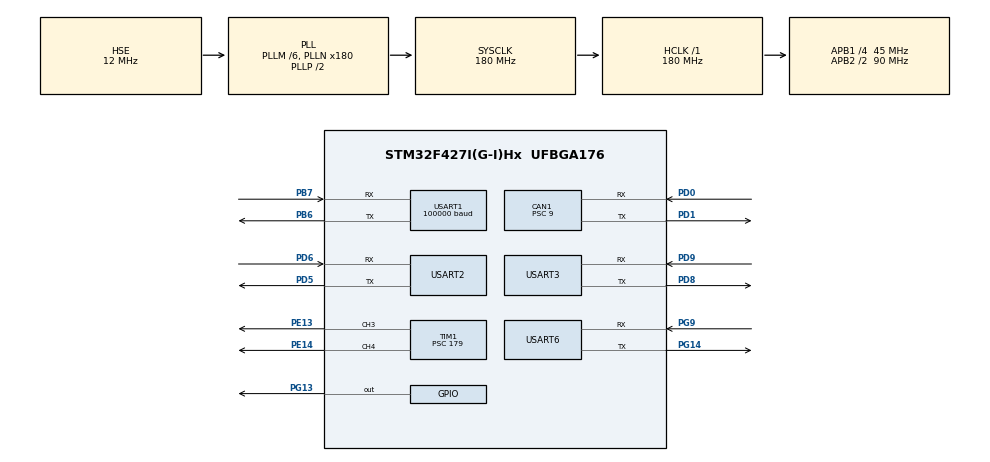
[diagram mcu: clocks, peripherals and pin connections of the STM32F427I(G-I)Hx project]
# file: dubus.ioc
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CAN1.ABOM=ENABLE
CAN1.BS1=CAN_BS1_2TQ
CAN1.BS2=CAN_BS2_2TQ
CAN1.CalculateTimeQuantum=200.0
CAN1.Prescaler=9
CAN1.SJW=CAN_SJW_4TQ
Dma.Request0=USART3_RX
Dma.Request1=USART6_RX
Dma.Request2=USART1_RX
Dma.USART1_RX.2.Direction=DMA_PERIPH_TO_MEMORY
Dma.USART1_RX.2.FIFOMode=DMA_FIFOMODE_DISABLE
Dma.USART1_RX.2.Instance=DMA2_Stream2
Dma.USART1_RX.2.MemDataAlignment=DMA_MDATAALIGN_BYTE
Dma.USART1_RX.2.MemInc=DMA_MINC_ENABLE
Dma.USART1_RX.2.Mode=DMA_NORMAL
Dma.USART1_RX.2.PeriphDataAlignment=DMA_PDATAALIGN_BYTE
Dma.USART1_RX.2.PeriphInc=DMA_PINC_DISABLE
Dma.USART1_RX.2.Priority=DMA_PRIORITY_HIGH
Dma.USART3_RX.0.Direction=DMA_PERIPH_TO_MEMORY
Dma.USART3_RX.0.FIFOMode=DMA_FIFOMODE_DISABLE
Dma.USART3_RX.0.Instance=DMA1_Stream1
Dma.USART3_RX.0.MemDataAlignment=DMA_MDATAALIGN_BYTE
Dma.USART3_RX.0.MemInc=DMA_MINC_ENABLE
Dma.USART3_RX.0.Mode=DMA_NORMAL
Dma.USART3_RX.0.PeriphDataAlignment=DMA_PDATAALIGN_BYTE
Dma.USART3_RX.0.PeriphInc=DMA_PINC_DISABLE
Dma.USART3_RX.0.Priority=DMA_PRIORITY_HIGH
Dma.USART6_RX.1.Direction=DMA_PERIPH_TO_MEMORY
Dma.USART6_RX.1.FIFOMode=DMA_FIFOMODE_DISABLE
Dma.USART6_RX.1.Instance=DMA2_Stream1
Dma.USART6_RX.1.MemDataAlignment=DMA_MDATAALIGN_BYTE
Dma.USART6_RX.1.MemInc=DMA_MINC_ENABLE
Dma.USART6_RX.1.Mode=DMA_NORMAL
Dma.USART6_RX.1.PeriphDataAlignment=DMA_PDATAALIGN_BYTE
Dma.USART6_RX.1.PeriphInc=DMA_PINC_DISABLE
Dma.USART6_RX.1.Priority=DMA_PRIORITY_LOW
Mcu.Family=STM32F4
Mcu.Name=STM32F427I(G-I)Hx
Mcu.Package=UFBGA176
NVIC.CAN1_RX0_IRQn=true\:2\:0\:true\:false\:true\:true
NVIC.DMA1_Stream1_IRQn=true\:0\:0\:false\:false\:true\:false
NVIC.DMA2_Stream1_IRQn=true\:0\:0\:false\:false\:true\:false
NVIC.DMA2_Stream2_IRQn=true\:1\:0\:true\:false\:true\:false
NVIC.PriorityGroup=NVIC_PRIORITYGROUP_4
NVIC.TIM7_IRQn=true\:3\:0\:true\:false\:true\:true
NVIC.USART1_IRQn=true\:1\:0\:true\:false\:true\:true
NVIC.USART3_IRQn=true\:1\:0\:true\:false\:true\:true
NVIC.USART6_IRQn=true\:2\:0\:true\:false\:true\:true
PA13.Mode=Serial_Wire
PA13.Signal=SYS_JTMS-SWDIO
PA14.Mode=Serial_Wire
PA14.Signal=SYS_JTCK-SWCLK
PB6.Mode=Asynchronous
PB6.Signal=USART1_TX
PB7.Mode=Asynchronous
PB7.Signal=USART1_RX
PD0.GPIO_PuPd=GPIO_PULLUP
PD0.GPIO_Speed=GPIO_SPEED_FREQ_VERY_HIGH
PD0.Mode=Master
PD0.Signal=CAN1_RX
PD1.GPIO_PuPd=GPIO_PULLUP
PD1.Mode=Master
PD1.Signal=CAN1_TX
PD5.Mode=Asynchronous
PD5.Signal=USART2_TX
PD6.Mode=Asynchronous
PD6.Signal=USART2_RX
PD8.Mode=Asynchronous
PD8.Signal=USART3_TX
PD9.Mode=Asynchronous
PD9.Signal=USART3_RX
PE13.Signal=S_TIM1_CH3
PE14.Signal=S_TIM1_CH4
PG13.GPIO_PuPd=GPIO_NOPULL
PG13.PinState=GPIO_PIN_RESET
PG13.Signal=GPIO_Output
PG14.Mode=Asynchronous
PG14.Signal=USART6_TX
PG9.Mode=Asynchronous
PG9.Signal=USART6_RX
PH0/OSC_IN.Mode=HSE-External-Oscillator
PH0/OSC_IN.Signal=RCC_OSC_IN
PH1/OSC_OUT.Mode=HSE-External-Oscillator
PH1/OSC_OUT.Signal=RCC_OSC_OUT
ProjectManager.HeapSize=0x200
ProjectManager.StackSize=0x400
ProjectManager.TargetToolchain=MDK-ARM V5
RCC.48MHZClocksFreq_Value=90000000
RCC.AHBFreq_Value=180000000
RCC.APB1CLKDivider=RCC_HCLK_DIV4
RCC.APB1Freq_Value=45000000
RCC.APB1TimFreq_Value=90000000
RCC.APB2CLKDivider=RCC_HCLK_DIV2
RCC.APB2Freq_Value=90000000
RCC.APB2TimFreq_Value=180000000
RCC.CortexFreq_Value=180000000
RCC.HCLKFreq_Value=180000000
RCC.HSE_VALUE=12000000
RCC.HSI_VALUE=16000000
RCC.LSE_VALUE=32768
RCC.PLLM=6
RCC.PLLN=180
RCC.PLLSourceVirtual=RCC_PLLSOURCE_HSE
RCC.SYSCLKFreq_VALUE=180000000
RCC.SYSCLKSource=RCC_SYSCLKSOURCE_PLLCLK
RCC.VCOOutputFreq_Value=360000000
SH.S_TIM1_CH3.0=TIM1_CH3,PWM Generation3 CH3
SH.S_TIM1_CH4.0=TIM1_CH4,PWM Generation4 CH4
TIM1.Channel-PWM\ Generation3\ CH3=TIM_CHANNEL_3
TIM1.Channel-PWM\ Generation4\ CH4=TIM_CHANNEL_4
TIM1.OCFastMode_PWM-PWM\ Generation3\ CH3=TIM_OCFAST_ENABLE
TIM1.OCFastMode_PWM-PWM\ Generation4\ CH4=TIM_OCFAST_ENABLE
TIM1.Period=19999
TIM1.Prescaler=179
TIM1.Pulse-PWM\ Generation3\ CH3=1000
TIM1.Pulse-PWM\ Generation4\ CH4=1000
TIM7.Period=999
TIM7.Prescaler=899
USART1.BaudRate=100000
USART1.Parity=PARITY_EVEN
USART1.VirtualMode=VM_ASYNC
USART2.VirtualMode=VM_ASYNC
USART3.VirtualMode=VM_ASYNC
USART6.VirtualMode=VM_ASYNC
VP_TIM7_VS_ClockSourceINT.Mode=Enable_Timer
board=custom

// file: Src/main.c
/**
  ******************************************************************************
  * @file           : main.c
  * @brief          : Main program body
  ******************************************************************************
  ** This notice applies to any and all portions of this file
  * that are not between comment pairs USER CODE BEGIN and
  * USER CODE END. Other portions of this file, whether
  * inserted by the user or by software development tools
  * are owned by their respective copyright owners.
  *
  * COPYRIGHT(c) 2018 STMicroelectronics
  *
  * Redistribution and use in source and binary forms, with or without modification,
  * are permitted provided that the following conditions are met:
  *   1. Redistributions of source code must retain the above copyright notice,
  *      this list of conditions and the following disclaimer.
  *   2. Redistributions in binary form must reproduce the above copyright notice,
  *      this list of conditions and the following disclaimer in the documentation
  *      and/or other materials provided with the distribution.
  *   3. Neither the name of STMicroelectronics nor the names of its contributors
  *      may be used to endorse or promote products derived from this software
  *      without specific prior written permission.
  *
  * THIS SOFTWARE IS PROVIDED BY THE COPYRIGHT HOLDERS AND CONTRIBUTORS "AS IS"
  * AND ANY EXPRESS OR IMPLIED WARRANTIES, INCLUDING, BUT NOT LIMITED TO, THE
  * IMPLIED WARRANTIES OF MERCHANTABILITY AND FITNESS FOR A PARTICULAR PURPOSE ARE
  * DISCLAIMED. IN NO EVENT SHALL THE COPYRIGHT HOLDER OR CONTRIBUTORS BE LIABLE
  * FOR ANY DIRECT, INDIRECT, INCIDENTAL, SPECIAL, EXEMPLARY, OR CONSEQUENTIAL
  * DAMAGES (INCLUDING, BUT NOT LIMITED TO, PROCUREMENT OF SUBSTITUTE GOODS OR
  * SERVICES; LOSS OF USE, DATA, OR PROFITS; OR BUSINESS INTERRUPTION) HOWEVER
  * CAUSED AND ON ANY THEORY OF LIABILITY, WHETHER IN CONTRACT, STRICT LIABILITY,
  * OR TORT (INCLUDING NEGLIGENCE OR OTHERWISE) ARISING IN ANY WAY OUT OF THE USE
  * OF THIS SOFTWARE, EVEN IF ADVISED OF THE POSSIBILITY OF SUCH DAMAGE.
  *
  ******************************************************************************
  */
#include "main.h"
#include "stm32f4xx_hal.h"

/* USER CODE BEGIN Includes */
#include "User.h"
/* USER CODE END Includes */

CAN_HandleTypeDef hcan1;

TIM_HandleTypeDef htim1;
TIM_HandleTypeDef htim7;

UART_HandleTypeDef huart1;
UART_HandleTypeDef huart2;
UART_HandleTypeDef huart3;
UART_HandleTypeDef huart6;
DMA_HandleTypeDef hdma_usart1_rx;
DMA_HandleTypeDef hdma_usart3_rx;
DMA_HandleTypeDef hdma_usart6_rx;

/* USER CODE BEGIN PV */
/* Private variables ---------------------------------------------------------*/
extern uint8_t aff;
/* USER CODE END PV */

void SystemClock_Config(void);
static void MX_GPIO_Init(void);
static void MX_DMA_Init(void);
static void MX_USART1_UART_Init(void);
static void MX_CAN1_Init(void);
static void MX_TIM7_Init(void);
static void MX_USART2_UART_Init(void);
static void MX_USART3_UART_Init(void);
static void MX_USART6_UART_Init(void);
static void MX_TIM1_Init(void);

void HAL_TIM_MspPostInit(TIM_HandleTypeDef *htim);

/* USER CODE BEGIN PFP */
/* Private function prototypes -----------------------------------------------*/

/* USER CODE END PFP */

/* USER CODE BEGIN 0 */
//extern Pantiltzoom_Struct Ps;	//云台对象
//unsigned char aaaa[13]= ",v1=10,v2=100";
/* USER CODE END 0 */

int main(void)
{

  /* MCU Configuration----------------------------------------------------------*/

  /* Reset of all peripherals, Initializes the Flash interface and the Systick. */
  HAL_Init();

  /* Configure the system clock */
  SystemClock_Config();

  /* Initialize all configured peripherals */
  MX_GPIO_Init();
  MX_DMA_Init();
  MX_USART1_UART_Init();
  MX_CAN1_Init();
  MX_TIM7_Init();
  MX_USART2_UART_Init();
  MX_USART3_UART_Init();
  MX_USART6_UART_Init();
  MX_TIM1_Init();
  /* USER CODE BEGIN 2 */
      User_config();//用户初始化函数
			HAL_Delay(50);
//			__HAL_UART_ENABLE_IT(&huart1,UART_IT_IDLE );//串口1空闲中断使能
  /* USER CODE END 2 */

  /* Infinite loop */
  while (1)
  {

  }

}

void SystemClock_Config(void)
{

  RCC_OscInitTypeDef RCC_OscInitStruct;
  RCC_ClkInitTypeDef RCC_ClkInitStruct;

    /**Configure the main internal regulator output voltage
    */
  __HAL_RCC_PWR_CLK_ENABLE();

  __HAL_PWR_VOLTAGESCALING_CONFIG(PWR_REGULATOR_VOLTAGE_SCALE1);

    /**Initializes the CPU, AHB and APB busses clocks
    */
  RCC_OscInitStruct.OscillatorType = RCC_OSCILLATORTYPE_HSE;
  RCC_OscInitStruct.HSEState = RCC_HSE_ON;
  RCC_OscInitStruct.PLL.PLLState = RCC_PLL_ON;
  RCC_OscInitStruct.PLL.PLLSource = RCC_PLLSOURCE_HSE;
  RCC_OscInitStruct.PLL.PLLM = 6;
  RCC_OscInitStruct.PLL.PLLN = 180;
  RCC_OscInitStruct.PLL.PLLP = RCC_PLLP_DIV2;
  RCC_OscInitStruct.PLL.PLLQ = 4;
  if (HAL_RCC_OscConfig(&RCC_OscInitStruct) != HAL_OK)
  {
    _Error_Handler(__FILE__, __LINE__);
  }

    /**Activate the Over-Drive mode
    */
  if (HAL_PWREx_EnableOverDrive() != HAL_OK)
  {
    _Error_Handler(__FILE__, __LINE__);
  }

    /**Initializes the CPU, AHB and APB busses clocks
    */
  RCC_ClkInitStruct.ClockType = RCC_CLOCKTYPE_HCLK|RCC_CLOCKTYPE_SYSCLK
                              |RCC_CLOCKTYPE_PCLK1|RCC_CLOCKTYPE_PCLK2;
  RCC_ClkInitStruct.SYSCLKSource = RCC_SYSCLKSOURCE_PLLCLK;
  RCC_ClkInitStruct.AHBCLKDivider = RCC_SYSCLK_DIV1;
  RCC_ClkInitStruct.APB1CLKDivider = RCC_HCLK_DIV4;
  RCC_ClkInitStruct.APB2CLKDivider = RCC_HCLK_DIV2;

  if (HAL_RCC_ClockConfig(&RCC_ClkInitStruct, FLASH_LATENCY_5) != HAL_OK)
  {
    _Error_Handler(__FILE__, __LINE__);
  }

    /**Configure the Systick interrupt time
    */
  HAL_SYSTICK_Config(HAL_RCC_GetHCLKFreq()/1000);

    /**Configure the Systick
    */
  HAL_SYSTICK_CLKSourceConfig(SYSTICK_CLKSOURCE_HCLK);

  /* SysTick_IRQn interrupt configuration */
  HAL_NVIC_SetPriority(SysTick_IRQn, 0, 0);
}

/* CAN1 init function */
static void MX_CAN1_Init(void)
{

  hcan1.Instance = CAN1;
  hcan1.Init.Prescaler = 9;
  hcan1.Init.Mode = CAN_MODE_NORMAL;
  hcan1.Init.SyncJumpWidth = CAN_SJW_4TQ;
  hcan1.Init.TimeSeg1 = CAN_BS1_2TQ;
  hcan1.Init.TimeSeg2 = CAN_BS2_2TQ;
  hcan1.Init.TimeTriggeredMode = DISABLE;
  hcan1.Init.AutoBusOff = ENABLE;
  hcan1.Init.AutoWakeUp = DISABLE;
  hcan1.Init.AutoRetransmission = DISABLE;
  hcan1.Init.ReceiveFifoLocked = DISABLE;
  hcan1.Init.TransmitFifoPriority = DISABLE;
  if (HAL_CAN_Init(&hcan1) != HAL_OK)
  {
    _Error_Handler(__FILE__, __LINE__);
  }

}

/* TIM1 init function */
static void MX_TIM1_Init(void)
{

  TIM_MasterConfigTypeDef sMasterConfig;
  TIM_OC_InitTypeDef sConfigOC;
  TIM_BreakDeadTimeConfigTypeDef sBreakDeadTimeConfig;

  htim1.Instance = TIM1;
  htim1.Init.Prescaler = 179;
  htim1.Init.CounterMode = TIM_COUNTERMODE_UP;
  htim1.Init.Period = 19999;
  htim1.Init.ClockDivision = TIM_CLOCKDIVISION_DIV1;
  htim1.Init.RepetitionCounter = 0;
  if (HAL_TIM_PWM_Init(&htim1) != HAL_OK)
  {
    _Error_Handler(__FILE__, __LINE__);
  }

  sMasterConfig.MasterOutputTrigger = TIM_TRGO_RESET;
  sMasterConfig.MasterSlaveMode = TIM_MASTERSLAVEMODE_DISABLE;
  if (HAL_TIMEx_MasterConfigSynchronization(&htim1, &sMasterConfig) != HAL_OK)
  {
    _Error_Handler(__FILE__, __LINE__);
  }

  sConfigOC.OCMode = TIM_OCMODE_PWM1;
  sConfigOC.Pulse = 1000;
  sConfigOC.OCPolarity = TIM_OCPOLARITY_HIGH;
  sConfigOC.OCNPolarity = TIM_OCNPOLARITY_HIGH;
  sConfigOC.OCFastMode = TIM_OCFAST_ENABLE;
  sConfigOC.OCIdleState = TIM_OCIDLESTATE_RESET;
  sConfigOC.OCNIdleState = TIM_OCNIDLESTATE_RESET;
  if (HAL_TIM_PWM_ConfigChannel(&htim1, &sConfigOC, TIM_CHANNEL_3) != HAL_OK)
  {
    _Error_Handler(__FILE__, __LINE__);
  }

  if (HAL_TIM_PWM_ConfigChannel(&htim1, &sConfigOC, TIM_CHANNEL_4) != HAL_OK)
  {
    _Error_Handler(__FILE__, __LINE__);
  }

  sBreakDeadTimeConfig.OffStateRunMode = TIM_OSSR_DISABLE;
  sBreakDeadTimeConfig.OffStateIDLEMode = TIM_OSSI_DISABLE;
  sBreakDeadTimeConfig.LockLevel = TIM_LOCKLEVEL_OFF;
  sBreakDeadTimeConfig.DeadTime = 0;
  sBreakDeadTimeConfig.BreakState = TIM_BREAK_DISABLE;
  sBreakDeadTimeConfig.BreakPolarity = TIM_BREAKPOLARITY_HIGH;
  sBreakDeadTimeConfig.AutomaticOutput = TIM_AUTOMATICOUTPUT_DISABLE;
  if (HAL_TIMEx_ConfigBreakDeadTime(&htim1, &sBreakDeadTimeConfig) != HAL_OK)
  {
    _Error_Handler(__FILE__, __LINE__);
  }

  HAL_TIM_MspPostInit(&htim1);

}

/* TIM7 init function */
static void MX_TIM7_Init(void)
{

  TIM_MasterConfigTypeDef sMasterConfig;

  htim7.Instance = TIM7;
  htim7.Init.Prescaler = 899;
  htim7.Init.CounterMode = TIM_COUNTERMODE_UP;
  htim7.Init.Period = 999;
  if (HAL_TIM_Base_Init(&htim7) != HAL_OK)
  {
    _Error_Handler(__FILE__, __LINE__);
  }

  sMasterConfig.MasterOutputTrigger = TIM_TRGO_RESET;
  sMasterConfig.MasterSlaveMode = TIM_MASTERSLAVEMODE_DISABLE;
  if (HAL_TIMEx_MasterConfigSynchronization(&htim7, &sMasterConfig) != HAL_OK)
  {
    _Error_Handler(__FILE__, __LINE__);
  }

}

/* USART1 init function */
static void MX_USART1_UART_Init(void)
{

  huart1.Instance = USART1;
  huart1.Init.BaudRate = 100000;
  huart1.Init.WordLength = UART_WORDLENGTH_8B;
  huart1.Init.StopBits = UART_STOPBITS_1;
  huart1.Init.Parity = UART_PARITY_EVEN;
  huart1.Init.Mode = UART_MODE_TX_RX;
  huart1.Init.HwFlowCtl = UART_HWCONTROL_NONE;
  huart1.Init.OverSampling = UART_OVERSAMPLING_16;
  if (HAL_UART_Init(&huart1) != HAL_OK)
  {
    _Error_Handler(__FILE__, __LINE__);
  }

}

/* USART2 init function */
static void MX_USART2_UART_Init(void)
{

  huart2.Instance = USART2;
  huart2.Init.BaudRate = 115200;
  huart2.Init.WordLength = UART_WORDLENGTH_8B;
  huart2.Init.StopBits = UART_STOPBITS_1;
  huart2.Init.Parity = UART_PARITY_NONE;
  huart2.Init.Mode = UART_MODE_TX_RX;
  huart2.Init.HwFlowCtl = UART_HWCONTROL_NONE;
  huart2.Init.OverSampling = UART_OVERSAMPLING_16;
  if (HAL_UART_Init(&huart2) != HAL_OK)
  {
    _Error_Handler(__FILE__, __LINE__);
  }

}

/* USART3 init function */
static void MX_USART3_UART_Init(void)
{

  huart3.Instance = USART3;
  huart3.Init.BaudRate = 115200;
  huart3.Init.WordLength = UART_WORDLENGTH_8B;
  huart3.Init.StopBits = UART_STOPBITS_1;
  huart3.Init.Parity = UART_PARITY_NONE;
  huart3.Init.Mode = UART_MODE_TX_RX;
  huart3.Init.HwFlowCtl = UART_HWCONTROL_NONE;
  huart3.Init.OverSampling = UART_OVERSAMPLING_16;
  if (HAL_UART_Init(&huart3) != HAL_OK)
  {
    _Error_Handler(__FILE__, __LINE__);
  }

}

/* USART6 init function */
static void MX_USART6_UART_Init(void)
{

  huart6.Instance = USART6;
  huart6.Init.BaudRate = 115200;
  huart6.Init.WordLength = UART_WORDLENGTH_8B;
  huart6.Init.StopBits = UART_STOPBITS_1;
  huart6.Init.Parity = UART_PARITY_NONE;
  huart6.Init.Mode = UART_MODE_TX_RX;
  huart6.Init.HwFlowCtl = UART_HWCONTROL_NONE;
  huart6.Init.OverSampling = UART_OVERSAMPLING_16;
  if (HAL_UART_Init(&huart6) != HAL_OK)
  {
    _Error_Handler(__FILE__, __LINE__);
  }

}

static void MX_DMA_Init(void)
{
  /* DMA controller clock enable */
  __HAL_RCC_DMA1_CLK_ENABLE();
  __HAL_RCC_DMA2_CLK_ENABLE();

  /* DMA interrupt init */
  /* DMA1_Stream1_IRQn interrupt configuration */
  HAL_NVIC_SetPriority(DMA1_Stream1_IRQn, 0, 0);
  HAL_NVIC_EnableIRQ(DMA1_Stream1_IRQn);
  /* DMA2_Stream1_IRQn interrupt configuration */
  HAL_NVIC_SetPriority(DMA2_Stream1_IRQn, 0, 0);
  HAL_NVIC_EnableIRQ(DMA2_Stream1_IRQn);
  /* DMA2_Stream2_IRQn interrupt configuration */
  HAL_NVIC_SetPriority(DMA2_Stream2_IRQn, 1, 0);
  HAL_NVIC_EnableIRQ(DMA2_Stream2_IRQn);

}

/** Configure pins as
        * Analog
        * Input
        * Output
        * EVENT_OUT
        * EXTI
*/
static void MX_GPIO_Init(void)
{

  GPIO_InitTypeDef GPIO_InitStruct;

  /* GPIO Ports Clock Enable */
  __HAL_RCC_GPIOG_CLK_ENABLE();
  __HAL_RCC_GPIOA_CLK_ENABLE();
  __HAL_RCC_GPIOB_CLK_ENABLE();
  __HAL_RCC_GPIOD_CLK_ENABLE();
  __HAL_RCC_GPIOH_CLK_ENABLE();
  __HAL_RCC_GPIOE_CLK_ENABLE();

  /*Configure GPIO pin Output Level */
  HAL_GPIO_WritePin(GPIOG, GPIO_PIN_13, GPIO_PIN_RESET);

  /*Configure GPIO pin : PG13 */
  GPIO_InitStruct.Pin = GPIO_PIN_13;
  GPIO_InitStruct.Mode = GPIO_MODE_OUTPUT_PP;
  GPIO_InitStruct.Pull = GPIO_NOPULL;
  GPIO_InitStruct.Speed = GPIO_SPEED_FREQ_LOW;
  HAL_GPIO_Init(GPIOG, &GPIO_InitStruct);

}

void _Error_Handler(char *file, int line)
{
  while(1)
  {
  }
}

/************************ (C) COPYRIGHT STMicroelectronics *****END OF FILE****/
